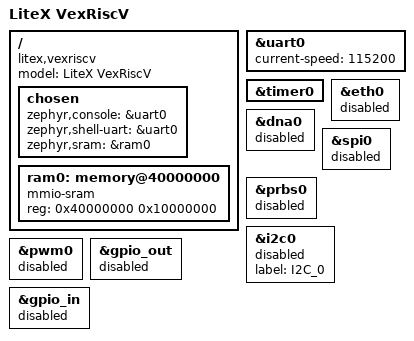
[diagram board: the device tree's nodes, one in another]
/*
 * Copyright (c) 2018 - 2019 Antmicro <www.antmicro.com>
 *
 * SPDX-License-Identifier: Apache-2.0
 */

/dts-v1/;

#include <riscv32-litex-vexriscv.dtsi>

/ {
	model = "LiteX VexRiscV";
	compatible = "litex,vexriscv";
	chosen {
		zephyr,console = &uart0;
		zephyr,shell-uart = &uart0;
		zephyr,sram = &ram0;
	};

	ram0: memory@40000000 {
		device_type = "memory";
		compatible = "mmio-sram";
		reg = <0x40000000 0x10000000>;
	};
};

&uart0 {
	status = "okay";
	current-speed = <115200>;
};

&timer0 {
	status = "okay";
};

&eth0 {
	status = "disabled";
};

&dna0 {
	status = "disabled";
};

&spi0 {
	status = "disabled";
};

&prbs0 {
	status = "disabled";
};

&i2c0 {
	status = "disabled";
	label = "I2C_0";
};

&pwm0 {
	status = "disabled";
};

&gpio_out {
	status = "disabled";
};

&gpio_in {
	status = "disabled";
};
